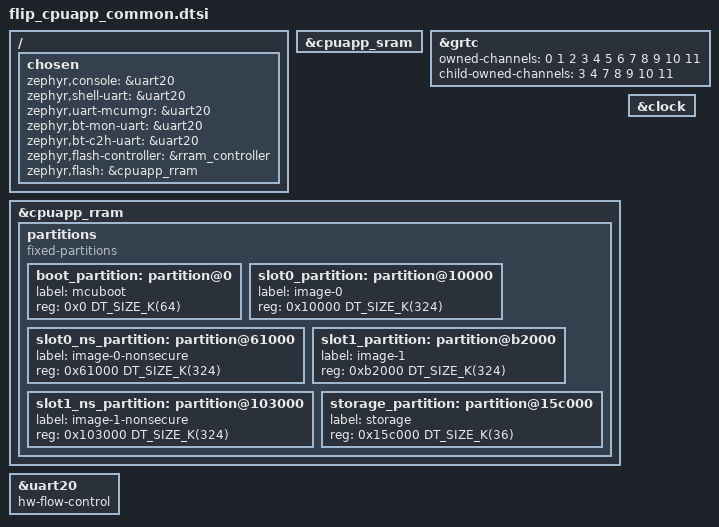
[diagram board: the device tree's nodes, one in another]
/*
 * Copyright (c) 2024 Nordic Semiconductor ASA
 *
 * SPDX-License-Identifier: Apache-2.0
 */

/* This file is common to the secure and non-secure domain */

#include <nordic/flip_cpuapp.dtsi>
#include "flipdk_flip_common.dtsi"

/ {
	chosen {
		zephyr,console = &uart20;
		zephyr,shell-uart = &uart20;
		zephyr,uart-mcumgr = &uart20;
		zephyr,bt-mon-uart = &uart20;
		zephyr,bt-c2h-uart = &uart20;
		zephyr,flash-controller = &rram_controller;
		zephyr,flash = &cpuapp_rram;
	};
};

&cpuapp_sram {
	status = "okay";
};

&grtc {
	owned-channels = <0 1 2 3 4 5 6 7 8 9 10 11>;
	/* Channels 7-11 reserved for Zero Latency IRQs, 3-4 for FLPR */
	child-owned-channels = <3 4 7 8 9 10 11>;
	status = "okay";
};

&cpuapp_rram {
	partitions {
		compatible = "fixed-partitions";
		#address-cells = <1>;
		#size-cells = <1>;
		boot_partition: partition@0 {
			label = "mcuboot";
			reg = <0x0 DT_SIZE_K(64)>;
		};
		slot0_partition: partition@10000 {
			label = "image-0";
			reg = <0x10000 DT_SIZE_K(324)>;
		};
		slot0_ns_partition: partition@61000 {
			label = "image-0-nonsecure";
			reg = <0x61000 DT_SIZE_K(324)>;
		};
		slot1_partition: partition@b2000 {
			label = "image-1";
			reg = <0xb2000 DT_SIZE_K(324)>;
		};
		slot1_ns_partition: partition@103000 {
			label = "image-1-nonsecure";
			reg = <0x103000 DT_SIZE_K(324)>;
		};
		/* 32k from 0x154000 to 0x15bfff reserved for TF-M partitions */
		storage_partition: partition@15c000 {
			label = "storage";
			reg = <0x15c000 DT_SIZE_K(36)>;
		};
	};
};

&uart20 {
	status = "okay";
	hw-flow-control;
};

&clock {
	status = "okay";
};
